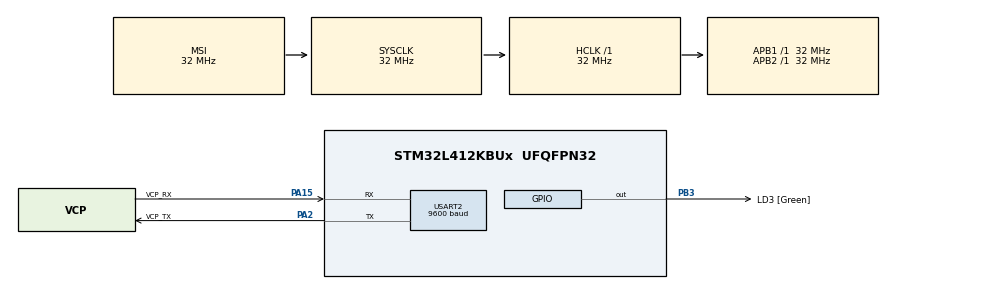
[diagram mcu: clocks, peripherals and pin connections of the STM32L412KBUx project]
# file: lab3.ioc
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Mcu.Family=STM32L4
Mcu.Name=STM32L412KBUx
Mcu.Package=UFQFPN32
NVIC.PriorityGroup=NVIC_PRIORITYGROUP_4
NVIC.USART2_IRQn=true\:0\:0\:false\:false\:true\:true\:true
PA0-CK_IN.Mode=HSE-External-Clock-Source-for-LittleOrca
PA0-CK_IN.Signal=RCC_CK_IN
PA13\ (JTMS/SWDIO).GPIO_Label=SWDIO
PA13\ (JTMS/SWDIO).Mode=Serial_Wire
PA13\ (JTMS/SWDIO).Signal=SYS_JTMS-SWDIO
PA14\ (JTCK/SWCLK).GPIO_Label=SWCLK
PA14\ (JTCK/SWCLK).Mode=Serial_Wire
PA14\ (JTCK/SWCLK).Signal=SYS_JTCK-SWCLK
PA15\ (JTDI).GPIO_Label=VCP_RX
PA15\ (JTDI).Mode=Asynchronous
PA15\ (JTDI).Signal=USART2_RX
PA2.GPIO_Label=VCP_TX
PA2.Mode=Asynchronous
PA2.Signal=USART2_TX
PB3\ (JTDO/TRACESWO).GPIO_Label=LD3 [Green]
PB3\ (JTDO/TRACESWO).Signal=GPIO_Output
PC14-OSC32_IN\ (PC14).Mode=LSE-External-Oscillator
PC14-OSC32_IN\ (PC14).Signal=RCC_OSC32_IN
PC15-OSC32_OUT\ (PC15).Mode=LSE-External-Oscillator
PC15-OSC32_OUT\ (PC15).Signal=RCC_OSC32_OUT
ProjectManager.HeapSize=0x200
ProjectManager.StackSize=0x400
ProjectManager.TargetToolchain=Makefile
RCC.ADCFreq_Value=32000000
RCC.AHBFreq_Value=32000000
RCC.APB1Freq_Value=32000000
RCC.APB1TimFreq_Value=32000000
RCC.APB2Freq_Value=32000000
RCC.APB2TimFreq_Value=32000000
RCC.CortexFreq_Value=32000000
RCC.FLatency=FLASH_LATENCY_1
RCC.HCLKFreq_Value=32000000
RCC.HSE_VALUE=8000000
RCC.HSI48_VALUE=48000000
RCC.HSICalibrationValue=16
RCC.HSI_VALUE=16000000
RCC.LSE_Drive_Capability=RCC_LSEDRIVE_LOW
RCC.MSIClockRange=RCC_MSIRANGE_10
RCC.MSI_VALUE=32000000
RCC.SYSCLKFreq_VALUE=32000000
RCC.USBFreq_Value=32000000
RCC.VCOOutputFreq_Value=256000000
USART2.BaudRate=9600
USART2.VirtualMode-Asynchronous=VM_ASYNC
board=NUCLEO-L412KB

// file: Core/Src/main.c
/* USER CODE BEGIN Header */
/**
  ******************************************************************************
  * @file           : main.c
  * @brief          : Main program body
  ******************************************************************************
  * @attention
  *
  * Copyright (c) 2022 STMicroelectronics.
  * All rights reserved.
  *
  * This software is licensed under terms that can be found in the LICENSE file
  * in the root directory of this software component.
  * If no LICENSE file comes with this software, it is provided AS-IS.
  *
  ******************************************************************************
  */
/* USER CODE END Header */
#include "main.h"

/* USER CODE BEGIN Includes */
#include <stdlib.h>
#include <stdio.h>
#include "stm32l4xx_ll_usart.h"
#include <string.h>
#include <retarget.h>
#include <command.h>
#include "queue.h"
/* USER CODE END Includes */

UART_HandleTypeDef huart2;

/* USER CODE BEGIN PV */
queue_t rx_queue;
int led_on = 0;
/* USER CODE END PV */

void SystemClock_Config(void);
static void MX_GPIO_Init(void);
static void MX_USART2_UART_Init(void);

/* USER CODE BEGIN PFP */
void help_command(char *args);
void lof_command();
void lon_command();
void test_command(char *args);
int parse_command (uint8_t *line, uint8_t **command, uint8_t **args);
int execute_command(uint8_t * line);
/* USER CODE END PFP */

/* USER CODE BEGIN 0 */
command_t commands[] = {
  {"help",help_command},
  {"lof",lof_command},
  {"lon",lon_command},
  {"test",test_command},
  {0,0}
};

/* USER CODE END 0 */

int main(void)
{

  /* MCU Configuration--------------------------------------------------------*/

  /* Reset of all peripherals, Initializes the Flash interface and the Systick. */
  HAL_Init();

  /* USER CODE BEGIN Init */
  uint8_t command_line[QUEUE_SIZE];
  uint8_t ch;
  int n = 0;
  /* USER CODE END Init */

  /* Configure the system clock */
  SystemClock_Config();

  /* Initialize all configured peripherals */
  MX_GPIO_Init();
  MX_USART2_UART_Init();

  /* USER CODE BEGIN 2 */
  RetargetInit(&huart2);
  LL_USART_EnableIT_RXNE(USART2);
  printf("\r\nSystem Running\n\r");
  printf("\r\nSTM$");
  /* USER CODE END 2 */

  /* Infinite loop */
  /* USER CODE BEGIN WHILE */
  while (1)
  {

    if ((ch = dequeue(&rx_queue))) {
      putchar(ch);
      command_line[n] = ch;
      if(ch == '\r' || ch == '\n'){
	command_line[n] = '\0'; //end of string
      	if(!execute_command(command_line)){
	  printf("\r\nOK");
	}else{
	  printf("\r\nNOK");
	}
	n = 0;
	printf("\r\nSTM$");
      }else{
	n++;
      }

    }
  }

    /* USER CODE END WHILE */

}

void SystemClock_Config(void)
{
  RCC_OscInitTypeDef RCC_OscInitStruct = {0};
  RCC_ClkInitTypeDef RCC_ClkInitStruct = {0};

  /** Configure the main internal regulator output voltage
  */
  if (HAL_PWREx_ControlVoltageScaling(PWR_REGULATOR_VOLTAGE_SCALE1) != HAL_OK)
  {
    Error_Handler();
  }
  /** Configure LSE Drive Capability
  */
  HAL_PWR_EnableBkUpAccess();
  __HAL_RCC_LSEDRIVE_CONFIG(RCC_LSEDRIVE_LOW);
  /** Initializes the RCC Oscillators according to the specified parameters
  * in the RCC_OscInitTypeDef structure.
  */
  RCC_OscInitStruct.OscillatorType = RCC_OSCILLATORTYPE_LSE|RCC_OSCILLATORTYPE_MSI;
  RCC_OscInitStruct.LSEState = RCC_LSE_ON;
  RCC_OscInitStruct.MSIState = RCC_MSI_ON;
  RCC_OscInitStruct.MSICalibrationValue = 0;
  RCC_OscInitStruct.MSIClockRange = RCC_MSIRANGE_10;
  RCC_OscInitStruct.PLL.PLLState = RCC_PLL_NONE;
  if (HAL_RCC_OscConfig(&RCC_OscInitStruct) != HAL_OK)
  {
    Error_Handler();
  }
  /** Initializes the CPU, AHB and APB buses clocks
  */
  RCC_ClkInitStruct.ClockType = RCC_CLOCKTYPE_HCLK|RCC_CLOCKTYPE_SYSCLK
                              |RCC_CLOCKTYPE_PCLK1|RCC_CLOCKTYPE_PCLK2;
  RCC_ClkInitStruct.SYSCLKSource = RCC_SYSCLKSOURCE_MSI;
  RCC_ClkInitStruct.AHBCLKDivider = RCC_SYSCLK_DIV1;
  RCC_ClkInitStruct.APB1CLKDivider = RCC_HCLK_DIV1;
  RCC_ClkInitStruct.APB2CLKDivider = RCC_HCLK_DIV1;

  if (HAL_RCC_ClockConfig(&RCC_ClkInitStruct, FLASH_LATENCY_1) != HAL_OK)
  {
    Error_Handler();
  }
  /** Enable MSI Auto calibration
  */
  HAL_RCCEx_EnableMSIPLLMode();
}

static void MX_USART2_UART_Init(void)
{

  huart2.Instance = USART2;
  huart2.Init.BaudRate = 9600;
  huart2.Init.WordLength = UART_WORDLENGTH_8B;
  huart2.Init.StopBits = UART_STOPBITS_1;
  huart2.Init.Parity = UART_PARITY_NONE;
  huart2.Init.Mode = UART_MODE_TX_RX;
  huart2.Init.HwFlowCtl = UART_HWCONTROL_NONE;
  huart2.Init.OverSampling = UART_OVERSAMPLING_16;
  huart2.Init.OneBitSampling = UART_ONE_BIT_SAMPLE_DISABLE;
  huart2.AdvancedInit.AdvFeatureInit = UART_ADVFEATURE_NO_INIT;
  if (HAL_UART_Init(&huart2) != HAL_OK)
  {
    Error_Handler();
  }

}

static void MX_GPIO_Init(void)
{
  GPIO_InitTypeDef GPIO_InitStruct = {0};

  /* GPIO Ports Clock Enable */
  __HAL_RCC_GPIOC_CLK_ENABLE();
  __HAL_RCC_GPIOA_CLK_ENABLE();
  __HAL_RCC_GPIOB_CLK_ENABLE();

  /*Configure GPIO pin Output Level */
  HAL_GPIO_WritePin(LD3_GPIO_Port, LD3_Pin, GPIO_PIN_RESET);

  /*Configure GPIO pin : LD3_Pin */
  GPIO_InitStruct.Pin = LD3_Pin;
  GPIO_InitStruct.Mode = GPIO_MODE_OUTPUT_PP;
  GPIO_InitStruct.Pull = GPIO_NOPULL;
  GPIO_InitStruct.Speed = GPIO_SPEED_FREQ_LOW;
  HAL_GPIO_Init(LD3_GPIO_Port, &GPIO_InitStruct);

}

/* USER CODE BEGIN 4 */
int execute_command(uint8_t * line) {
  uint8_t *cmd;
  uint8_t *arg;
  command_t *p = commands;
  int success = 0;

  if (!line) {
    return (-1); // Passed a bad pointer
  }
  if (parse_command(line,&cmd,&arg) == -1) {
    printf("Error with parse command\n\r");
    return (-1);
  }
  while (p->cmd_string) {
    if (!strcmp(p->cmd_string,(char *) cmd)) {
      if (!p->cmd_function) {
        return (-1);
      }
      (*p->cmd_function)((char *)arg);            // Run the command with the passed arguments
      success = 1;
      break;
    }
    p++;
  }
  if (success) {
    return (0);
  }
  else {
    return (-1);
  }
  }
int parse_command (uint8_t *line, uint8_t **command, uint8_t **args){

  uint8_t *line_temp;
  if((!line) || (!command) || (!args)){ //check for bad pointer
    return(-1);
  }
  line_temp= line;
  *command = line;
  //strcpy(line_left, line);
  while(*line_temp != ','){ //increment through input to find end of command
    if(!*line_temp){
      *args = '\0'; //no arguments
      return(0);
    }
    line_temp++;
  }

  *line_temp = '\0'; //replace comma with null for end of command string
  *args = line_temp +1; //one char past null is beginning of arguments
  return 0;
}
void help_command(char *args){
  printf("\r\nAvailable Commands:\n\r");
  printf("lon\n\r");
  printf("lof\n\r");
  printf("test\n\r");
}
void lon_command(){
  if(led_on == 0){
    HAL_GPIO_TogglePin(LD3_GPIO_Port, LD3_Pin);
    led_on = 1;
    printf("\r\nLED ON\n\r");
  }else{
    printf("\r\nLED ALREADY ON\n\r");
  }

}
void lof_command(){
  if(led_on == 1){
    HAL_GPIO_TogglePin(LD3_GPIO_Port, LD3_Pin);
    led_on = 0;
    printf("\r\nLED OFF\n\r");
  }else{
    printf("\r\nLED ALREADY OFF\n\r");
  }

}
void test_command(char *args){
  printf("\r\ntest\n\r");
  while(*args!='\0'){
    if(*args!=','){
      putchar(*args);
    }else{
      printf("\r\n");
    }
    args++;
  }
}

/* USER CODE END 4 */

void Error_Handler(void)
{
  __disable_irq();
  while (1)
  {
  }
}
